# PIC32MK1024GPL100 register map
Vendor: Microchip
Registers are 32-bit, read-write, no defined reset value unless marked. A register's access mark holds for its fields unless they carry their own. Addresses are absolute, and some are shared; only a register's first bit layout is shown; [hi:lo] are bit positions; {n}, {i} and the like mark numbered series.

## ADCHS
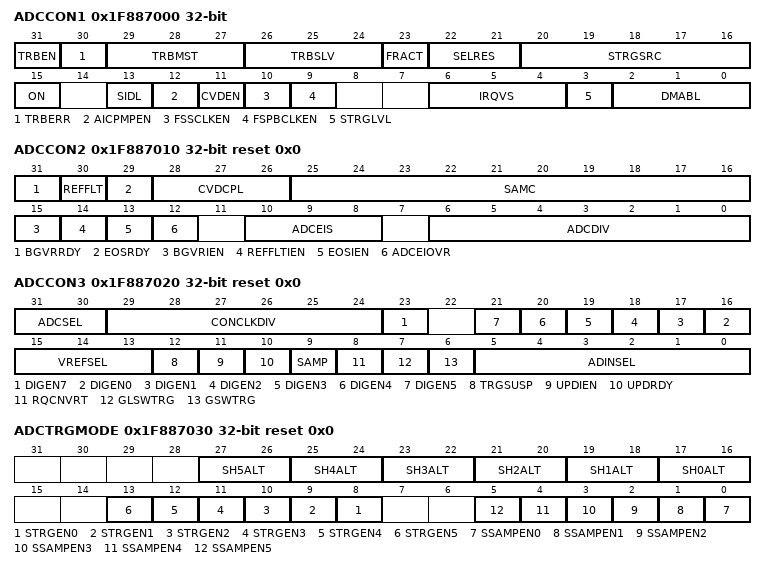
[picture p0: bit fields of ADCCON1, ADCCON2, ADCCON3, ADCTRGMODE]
0x1F887000 ADCCON1 — (power-on value 00000110000000000-00000--0000xxx)
  [31] TRBEN, [30] TRBERR ro, [29:27] TRBMST, [26:24] TRBSLV, [23] FRACT, [22:21] SELRES, [20:16] STRGSRC, [15] ON, [13] SIDL, [12] AICPMPEN, [11] CVDEN, [10] FSSCLKEN, [9] FSPBCLKEN, [6:4] IRQVS, [3] STRGLVL, [2:0] DMABL
0x1F887010 ADCCON2 reset 0x0
  [31] BGVRRDY ro, [30] REFFLT ro, [29] EOSRDY ro, [28:26] CVDCPL, [25:16] SAMC, [15] BGVRIEN, [14] REFFLTIEN, [13] EOSIEN, [12] ADCEIOVR, [10:8] ADCEIS, [6:0] ADCDIV
0x1F887020 ADCCON3 reset 0x0
  [31:30] ADCSEL, [29:24] CONCLKDIV, [23] DIGEN7 ro, [n+16] DIGEN{n} ro (n=0..5), [15:13] VREFSEL, [12] TRGSUSP, [11] UPDIEN, [10] UPDRDY, [9] SAMP, [8] RQCNVRT, [7] GLSWTRG, [6] GSWTRG, [5:0] ADINSEL
0x1F887030 ADCTRGMODE reset 0x0
  [2n+17:2n+16] SH{n}ALT (n=0..5), [n+8] STRGEN{n} (n=0..5), [n] SSAMPEN{n} (n=0..5)
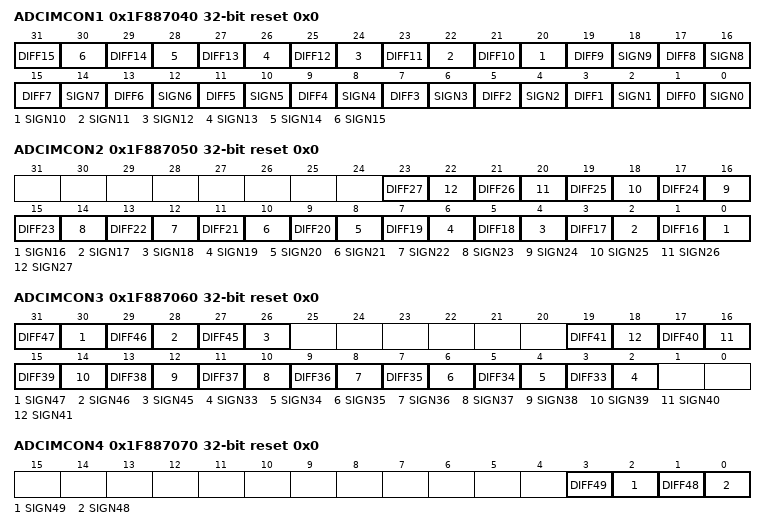
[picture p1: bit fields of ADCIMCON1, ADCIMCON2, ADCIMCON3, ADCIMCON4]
0x1F887040 ADCIMCON1 reset 0x0
  [2n+1] DIFF{n} (n=0..15), [2n] SIGN{n} (n=0..15)
0x1F887050 ADCIMCON2 reset 0x0
  [2n-31] DIFF{n} (n=16..27), [2n-32] SIGN{n} (n=16..27)
0x1F887060 ADCIMCON3 reset 0x0
  [31] DIFF47, [30] SIGN47, [29] DIFF46, [28] SIGN46, [27] DIFF45, [26] SIGN45, [2n-63] DIFF{n} (n=33..41), [2n-64] SIGN{n} (n=33..41)
0x1F887070 ADCIMCON4 reset 0x0
  [3] DIFF49, [2] SIGN49, [1] DIFF48, [0] SIGN48
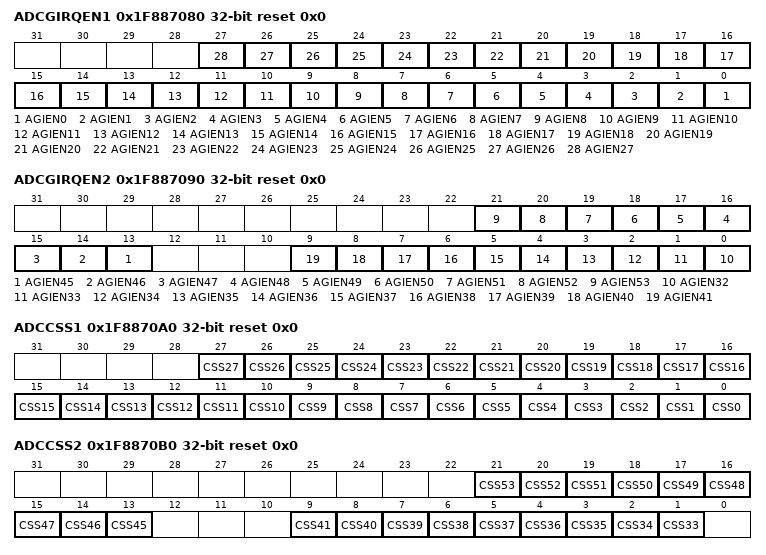
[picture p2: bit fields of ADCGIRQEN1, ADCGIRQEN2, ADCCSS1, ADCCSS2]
0x1F887080 ADCGIRQEN1 reset 0x0
  [n] AGIEN{n} (n=0..27)
0x1F887090 ADCGIRQEN2 reset 0x0
  [n-32] AGIEN{n} (n=45..53), [n-32] AGIEN{n} (n=32..41)
0x1F8870A0 ADCCSS1 reset 0x0
  [n] CSS{n} (n=0..27)
0x1F8870B0 ADCCSS2 reset 0x0
  [n-32] CSS{n} (n=45..53), [n-32] CSS{n} (n=33..41)
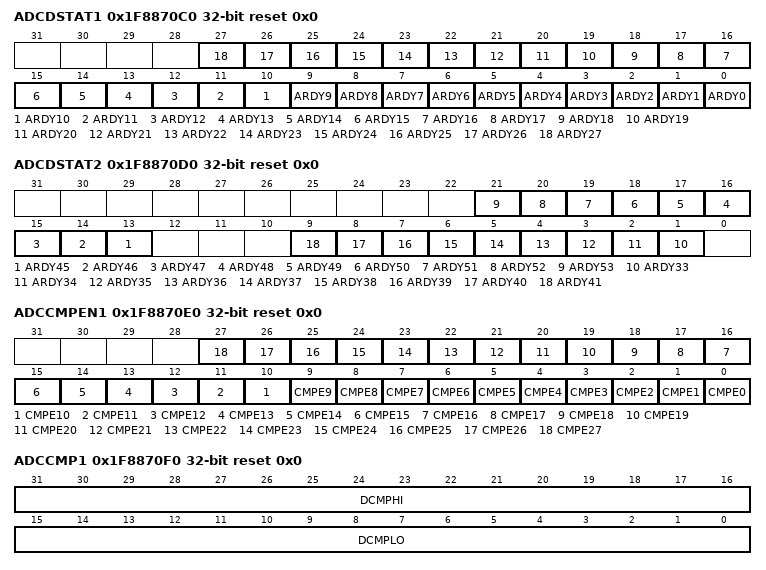
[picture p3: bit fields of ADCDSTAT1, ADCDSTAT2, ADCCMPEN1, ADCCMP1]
0x1F8870C0 ADCDSTAT1 ro reset 0x0
  [n] ARDY{n} (n=0..27)
0x1F8870D0 ADCDSTAT2 ro reset 0x0
  [n-32] ARDY{n} (n=45..53), [n-32] ARDY{n} (n=33..41)
0x1F8870E0 ADCCMPEN1 reset 0x0
  [n] CMPE{n} (n=0..27)
0x1F8870F0 ADCCMP1 reset 0x0
  [31:16] DCMPHI, [15:0] DCMPLO
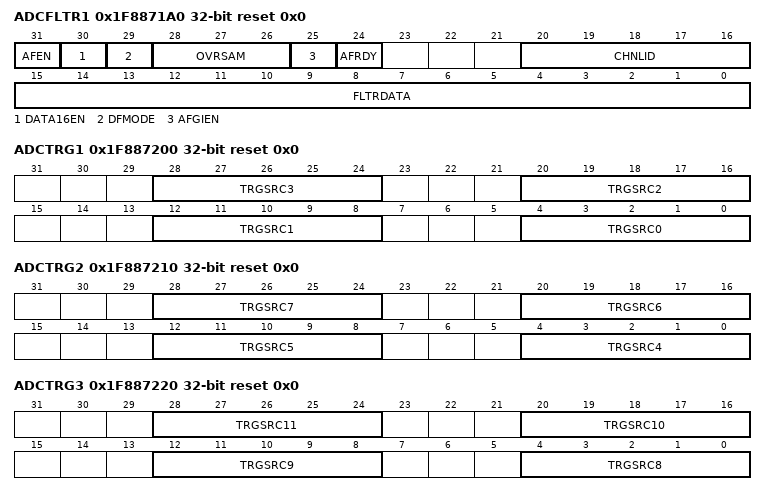
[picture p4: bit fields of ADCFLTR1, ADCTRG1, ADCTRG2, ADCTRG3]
0x1F8871A0 ADCFLTR1 reset 0x0
  [31] AFEN, [30] DATA16EN, [29] DFMODE, [28:26] OVRSAM, [25] AFGIEN, [24] AFRDY ro, [20:16] CHNLID, [15:0] FLTRDATA ro
0x1F887200 ADCTRG1 reset 0x0
  [8n+4:8n] TRGSRC{n} (n=0..3)
0x1F887210 ADCTRG2 reset 0x0
  [8n-28:8n-32] TRGSRC{n} (n=4..7)
0x1F887220 ADCTRG3 reset 0x0
  [8n-60:8n-64] TRGSRC{n} (n=8..11)
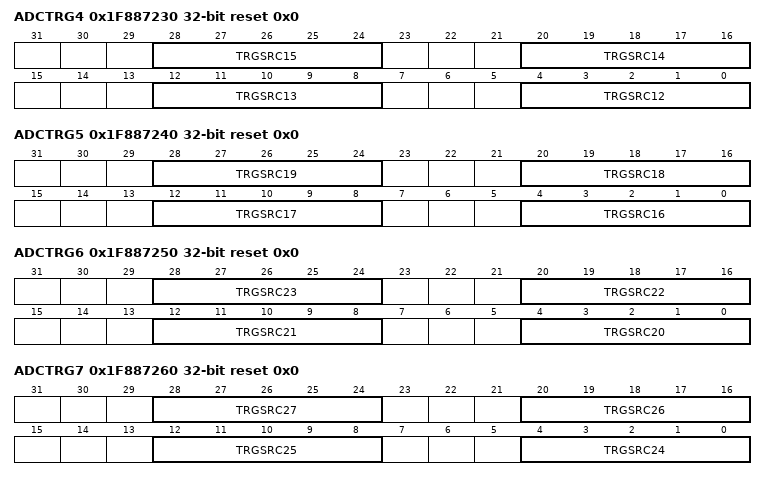
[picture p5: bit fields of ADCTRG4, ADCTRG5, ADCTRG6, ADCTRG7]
0x1F887230 ADCTRG4 reset 0x0
  [8n-92:8n-96] TRGSRC{n} (n=12..15)
0x1F887240 ADCTRG5 reset 0x0
  [8n-124:8n-128] TRGSRC{n} (n=16..19)
0x1F887250 ADCTRG6 reset 0x0
  [8n-156:8n-160] TRGSRC{n} (n=20..23)
0x1F887260 ADCTRG7 reset 0x0
  [8n-188:8n-192] TRGSRC{n} (n=24..27)
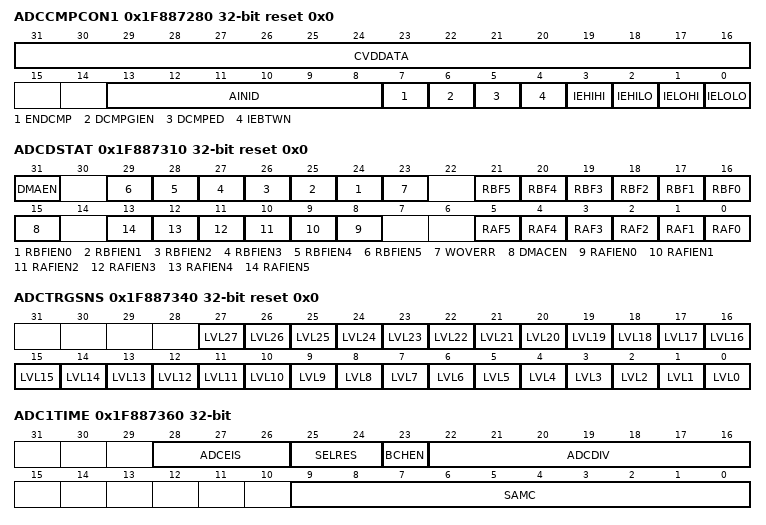
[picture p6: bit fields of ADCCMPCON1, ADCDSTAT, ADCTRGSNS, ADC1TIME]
0x1F887280 ADCCMPCON1 reset 0x0
  [31:16] CVDDATA ro, [13:8] AINID ro, [7] ENDCMP, [6] DCMPGIEN, [5] DCMPED ro, [4] IEBTWN, [3] IEHIHI, [2] IEHILO, [1] IELOHI, [0] IELOLO
0x1F887300 ADCBASE reset 0x0
  [15:0] ADCBASE
0x1F887310 ADCDSTAT reset 0x0
  [31] DMAEN, [n+24] RBFIEN{n} (n=0..5), [23] WOVERR ro, [n+16] RBF{n} ro (n=0..5), [15] DMACEN, [n+8] RAFIEN{n} (n=0..5), [n] RAF{n} ro (n=0..5)
0x1F887320 ADCCNTB reset 0x0
0x1F887330 ADCDMAB reset 0x0
0x1F887340 ADCTRGSNS reset 0x0
  [n] LVL{n} (n=0..27)
0x1F887360 ADC1TIME — (power-on value ---00000x0000000------0000000000)
  [28:26] ADCEIS, [25:24] SELRES, [23] BCHEN, [22:16] ADCDIV, [9:0] SAMC
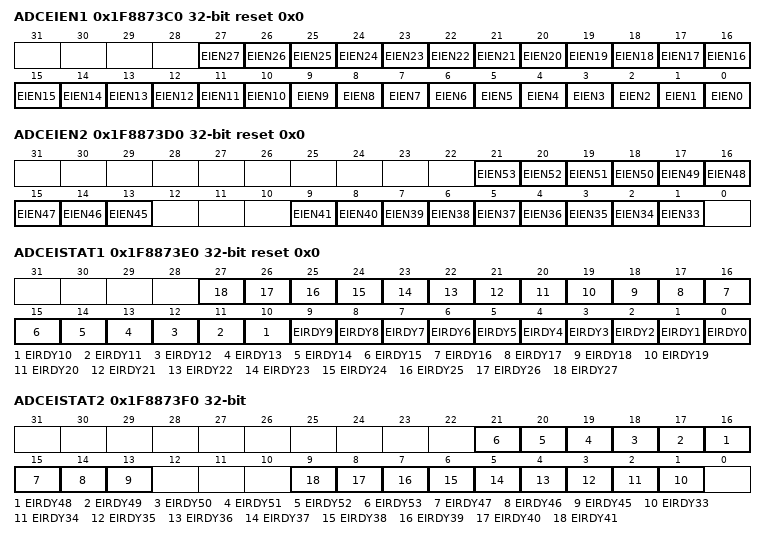
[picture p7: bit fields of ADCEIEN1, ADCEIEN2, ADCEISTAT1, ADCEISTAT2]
0x1F8873C0 ADCEIEN1 reset 0x0
  [n] EIEN{n} (n=0..27)
0x1F8873D0 ADCEIEN2 reset 0x0
  [n-32] EIEN{n} (n=45..53), [n-32] EIEN{n} (n=33..41)
0x1F8873E0 ADCEISTAT1 ro reset 0x0
  [n] EIRDY{n} (n=0..27)
0x1F8873F0 ADCEISTAT2 — (power-on value ----------xxxxxx000---000000000-)
  [n-32] EIRDY{n} (n=48..53), [15] EIRDY47 ro, [14] EIRDY46 ro, [13] EIRDY45 ro, [n-32] EIRDY{n} ro (n=33..41)
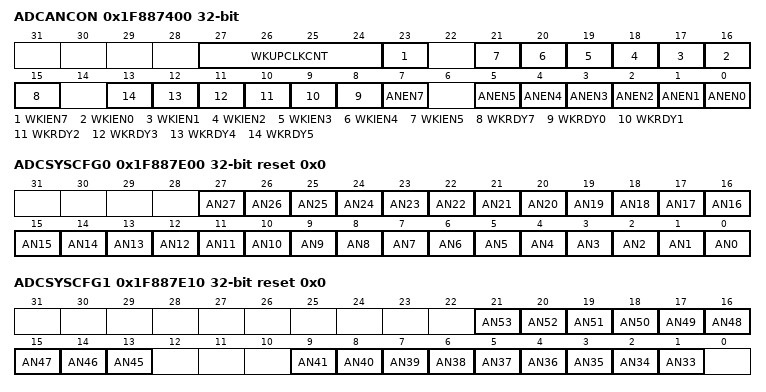
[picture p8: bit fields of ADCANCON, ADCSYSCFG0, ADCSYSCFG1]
0x1F887400 ADCANCON — (power-on value ----00000-x000000-0000000-000000)
  [27:24] WKUPCLKCNT, [23] WKIEN7, [n+16] WKIEN{n} (n=0..5), [15] WKRDY7 ro, [n+8] WKRDY{n} ro (n=0..5), [7] ANEN7, [n] ANEN{n} (n=0..5)
{0x1F887600+0x10*i} ADCDATA{i} reset 0x0 (i=0..27)
  [31:0] DATA
{0x1F887600+0x10*i} ADCDATA{i} reset 0x0 (i=33..41)
  [31:0] DATA
{0x1F887600+0x10*i} ADCDATA{i} reset 0x0 (i=45..53)
  [31:0] DATA
{0x1F887D00+0x10*i} ADC{i}CFG reset 0x0 (i=0..7)
  [31:0] ADCCFG
0x1F887E00 ADCSYSCFG0 ro reset 0x0
  [n] AN{n} (n=0..27)
0x1F887E10 ADCSYSCFG1 ro reset 0x0
  [n-32] AN{n} (n=45..53), [n-32] AN{n} (n=33..41)
